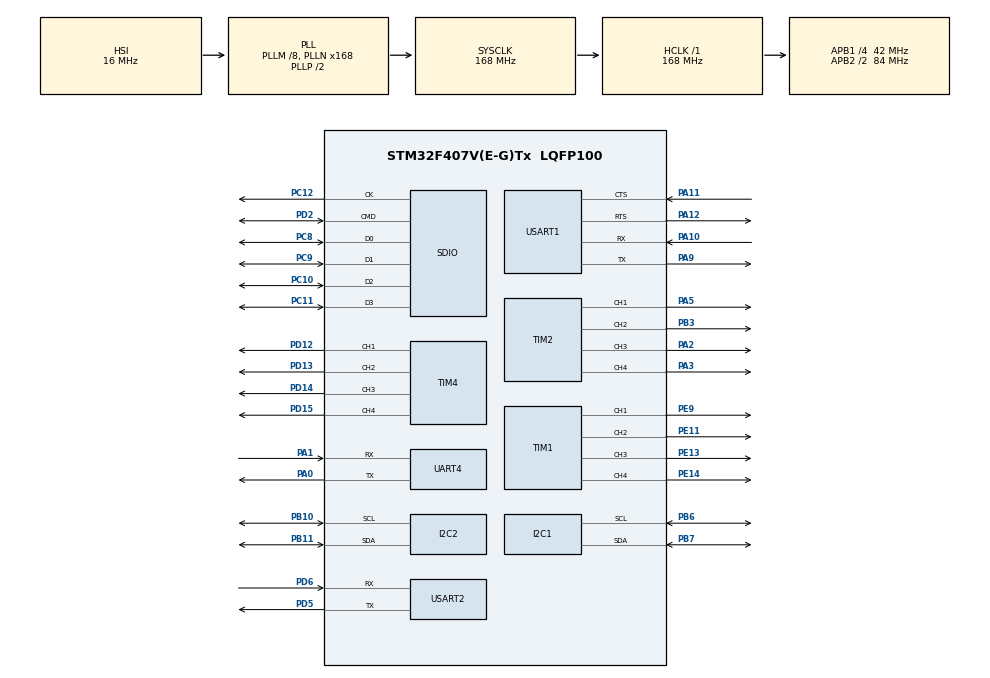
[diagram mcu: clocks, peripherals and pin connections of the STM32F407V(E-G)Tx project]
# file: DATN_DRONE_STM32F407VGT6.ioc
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FREERTOS.Tasks01=defaultTask,0,128,StartDefaultTask,Default,NULL,Dynamic,NULL,NULL
Mcu.Family=STM32F4
Mcu.Name=STM32F407V(E-G)Tx
Mcu.Package=LQFP100
NVIC.PriorityGroup=NVIC_PRIORITYGROUP_4
NVIC.TIM8_TRG_COM_TIM14_IRQn=true\:15\:0\:false\:false\:true\:false\:false\:true\:true
NVIC.TimeBase=TIM8_TRG_COM_TIM14_IRQn
NVIC.TimeBaseIP=TIM14
PA0-WKUP.Mode=Asynchronous
PA0-WKUP.Signal=UART4_TX
PA1.Mode=Asynchronous
PA1.Signal=UART4_RX
PA10.Mode=Asynchronous
PA10.Signal=USART1_RX
PA11.Mode=CTS_RTS
PA11.Signal=USART1_CTS
PA12.Mode=CTS_RTS
PA12.Signal=USART1_RTS
PA13.Mode=Serial_Wire
PA13.Signal=SYS_JTMS-SWDIO
PA14.Mode=Serial_Wire
PA14.Signal=SYS_JTCK-SWCLK
PA2.Signal=S_TIM2_CH3
PA3.Signal=S_TIM2_CH4
PA5.Signal=S_TIM2_CH1_ETR
PA9.Mode=Asynchronous
PA9.Signal=USART1_TX
PB10.Mode=I2C
PB10.Signal=I2C2_SCL
PB11.Mode=I2C
PB11.Signal=I2C2_SDA
PB3.Signal=S_TIM2_CH2
PB6.Mode=I2C
PB6.Signal=I2C1_SCL
PB7.Mode=I2C
PB7.Signal=I2C1_SDA
PC10.Mode=SD_4_bits_Wide_bus
PC10.Signal=SDIO_D2
PC11.Mode=SD_4_bits_Wide_bus
PC11.Signal=SDIO_D3
PC12.Mode=SD_4_bits_Wide_bus
PC12.Signal=SDIO_CK
PC8.Mode=SD_4_bits_Wide_bus
PC8.Signal=SDIO_D0
PC9.Mode=SD_4_bits_Wide_bus
PC9.Signal=SDIO_D1
PD12.Signal=S_TIM4_CH1
PD13.Signal=S_TIM4_CH2
PD14.Signal=S_TIM4_CH3
PD15.Signal=S_TIM4_CH4
PD2.Mode=SD_4_bits_Wide_bus
PD2.Signal=SDIO_CMD
PD5.Mode=Asynchronous
PD5.Signal=USART2_TX
PD6.Mode=Asynchronous
PD6.Signal=USART2_RX
PE11.Signal=S_TIM1_CH2
PE13.Signal=S_TIM1_CH3
PE14.Signal=S_TIM1_CH4
PE9.Signal=S_TIM1_CH1
PH0-OSC_IN.Mode=HSE-External-Oscillator
PH0-OSC_IN.Signal=RCC_OSC_IN
PH1-OSC_OUT.Mode=HSE-External-Oscillator
PH1-OSC_OUT.Signal=RCC_OSC_OUT
ProjectManager.HeapSize=0x200
ProjectManager.StackSize=0x400
ProjectManager.TargetToolchain=STM32CubeIDE
RCC.48MHZClocksFreq_Value=48000000
RCC.AHBFreq_Value=168000000
RCC.APB1CLKDivider=RCC_HCLK_DIV4
RCC.APB1Freq_Value=42000000
RCC.APB1TimFreq_Value=84000000
RCC.APB2CLKDivider=RCC_HCLK_DIV2
RCC.APB2Freq_Value=84000000
RCC.APB2TimFreq_Value=168000000
RCC.CortexFreq_Value=168000000
RCC.HCLKFreq_Value=168000000
RCC.HSE_VALUE=25000000
RCC.HSI_VALUE=16000000
RCC.LSE_VALUE=32768
RCC.PLLM=8
RCC.PLLN=168
RCC.PLLQ=7
RCC.SYSCLKFreq_VALUE=168000000
RCC.SYSCLKSource=RCC_SYSCLKSOURCE_PLLCLK
RCC.VCOOutputFreq_Value=336000000
SH.S_TIM1_CH1.0=TIM1_CH1,Output Compare1 CH1
SH.S_TIM1_CH2.0=TIM1_CH2,Output Compare2 CH2
SH.S_TIM1_CH3.0=TIM1_CH3,PWM Generation3 CH3
SH.S_TIM1_CH4.0=TIM1_CH4,PWM Generation4 CH4
SH.S_TIM2_CH1_ETR.0=TIM2_CH1,PWM Generation1 CH1
SH.S_TIM2_CH2.0=TIM2_CH2,PWM Generation2 CH2
SH.S_TIM2_CH3.0=TIM2_CH3,PWM Generation3 CH3
SH.S_TIM2_CH4.0=TIM2_CH4,PWM Generation4 CH4
SH.S_TIM4_CH1.0=TIM4_CH1,PWM Generation1 CH1
SH.S_TIM4_CH2.0=TIM4_CH2,PWM Generation2 CH2
SH.S_TIM4_CH3.0=TIM4_CH3,PWM Generation3 CH3
SH.S_TIM4_CH4.0=TIM4_CH4,PWM Generation4 CH4
TIM1.Channel-Output\ Compare1\ CH1=TIM_CHANNEL_1
TIM1.Channel-Output\ Compare2\ CH2=TIM_CHANNEL_2
TIM1.Channel-PWM\ Generation3\ CH3=TIM_CHANNEL_3
TIM1.Channel-PWM\ Generation4\ CH4=TIM_CHANNEL_4
TIM2.Channel-PWM\ Generation1\ CH1=TIM_CHANNEL_1
TIM2.Channel-PWM\ Generation2\ CH2=TIM_CHANNEL_2
TIM2.Channel-PWM\ Generation3\ CH3=TIM_CHANNEL_3
TIM2.Channel-PWM\ Generation4\ CH4=TIM_CHANNEL_4
TIM4.Channel-PWM\ Generation1\ CH1=TIM_CHANNEL_1
TIM4.Channel-PWM\ Generation2\ CH2=TIM_CHANNEL_2
TIM4.Channel-PWM\ Generation3\ CH3=TIM_CHANNEL_3
TIM4.Channel-PWM\ Generation4\ CH4=TIM_CHANNEL_4
UART4.VirtualMode=Asynchronous
USART1.VirtualMode=VM_ASYNC
USART2.VirtualMode=VM_ASYNC
VP_FREERTOS_VS_CMSIS_V1.Mode=CMSIS_V1
VP_SYS_VS_tim14.Mode=TIM14
VP_TIM1_VS_ClockSourceINT.Mode=Internal
VP_TIM2_VS_ClockSourceINT.Mode=Internal
VP_TIM4_VS_ClockSourceINT.Mode=Internal
board=custom

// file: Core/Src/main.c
/* USER CODE BEGIN Header */
/**
 ******************************************************************************
 * @file           : main.c
 * @brief          : Main program body
 ******************************************************************************
 * @attention
 *
 * Copyright (c) 2026 STMicroelectronics.
 * All rights reserved.
 *
 * This software is licensed under terms that can be found in the LICENSE file
 * in the root directory of this software component.
 * If no LICENSE file comes with this software, it is provided AS-IS.
 *
 ******************************************************************************
 */
/* USER CODE END Header */
#include "main.h"
#include "cmsis_os.h"
#include "i2c.h"
#include "sdio.h"
#include "tim.h"
#include "usart.h"
#include "gpio.h"

#include "app_main.h"

void SystemClock_Config(void);
void MX_FREERTOS_Init(void);

int main(void)
{

	/* MCU Configuration--------------------------------------------------------*/

	/* Reset of all peripherals, Initializes the Flash interface and the Systick. */
	HAL_Init();

	/* Configure the system clock */
	SystemClock_Config();

	/* Initialize all configured peripherals */
	MX_GPIO_Init();
	MX_I2C1_Init();
	MX_I2C2_Init();
	MX_SDIO_SD_Init();
	MX_TIM1_Init();
	MX_TIM2_Init();
	MX_TIM4_Init();
	MX_UART4_Init();
	MX_USART1_UART_Init();
	MX_USART2_UART_Init();
	/* USER CODE BEGIN 2 */
	if( createTasks() && initTasks())
	{
		// turn led
	}
	else
	{
		// khong cho chay chuong trinh
		while(1);
	}
	/* USER CODE END 2 */

	/* Call init function for freertos objects (in cmsis_os2.c) */
	MX_FREERTOS_Init();

	/* Start scheduler */
	//osKernelStart();
	vTaskStartScheduler();
	/* We should never get here as control is now taken by the scheduler */

	/* Infinite loop */
	while (1)
	{

	}
}

void SystemClock_Config(void)
{
	RCC_OscInitTypeDef RCC_OscInitStruct = {0};
	RCC_ClkInitTypeDef RCC_ClkInitStruct = {0};

	/** Configure the main internal regulator output voltage
	 */
	__HAL_RCC_PWR_CLK_ENABLE();
	__HAL_PWR_VOLTAGESCALING_CONFIG(PWR_REGULATOR_VOLTAGE_SCALE1);

	/** Initializes the RCC Oscillators according to the specified parameters
	 * in the RCC_OscInitTypeDef structure.
	 */
	RCC_OscInitStruct.OscillatorType = RCC_OSCILLATORTYPE_HSI;
	RCC_OscInitStruct.HSIState = RCC_HSI_ON;
	RCC_OscInitStruct.HSICalibrationValue = RCC_HSICALIBRATION_DEFAULT;
	RCC_OscInitStruct.PLL.PLLState = RCC_PLL_ON;
	RCC_OscInitStruct.PLL.PLLSource = RCC_PLLSOURCE_HSI;
	RCC_OscInitStruct.PLL.PLLM = 8;
	RCC_OscInitStruct.PLL.PLLN = 168;
	RCC_OscInitStruct.PLL.PLLP = RCC_PLLP_DIV2;
	RCC_OscInitStruct.PLL.PLLQ = 7;
	if (HAL_RCC_OscConfig(&RCC_OscInitStruct) != HAL_OK)
	{
		Error_Handler();
	}

	/** Initializes the CPU, AHB and APB buses clocks
	 */
	RCC_ClkInitStruct.ClockType = RCC_CLOCKTYPE_HCLK|RCC_CLOCKTYPE_SYSCLK
			|RCC_CLOCKTYPE_PCLK1|RCC_CLOCKTYPE_PCLK2;
	RCC_ClkInitStruct.SYSCLKSource = RCC_SYSCLKSOURCE_PLLCLK;
	RCC_ClkInitStruct.AHBCLKDivider = RCC_SYSCLK_DIV1;
	RCC_ClkInitStruct.APB1CLKDivider = RCC_HCLK_DIV4;
	RCC_ClkInitStruct.APB2CLKDivider = RCC_HCLK_DIV2;

	if (HAL_RCC_ClockConfig(&RCC_ClkInitStruct, FLASH_LATENCY_5) != HAL_OK)
	{
		Error_Handler();
	}
}

void HAL_TIM_PeriodElapsedCallback(TIM_HandleTypeDef *htim)
{
	if (htim->Instance == TIM14)
	{
		HAL_IncTick();
	}
}

void Error_Handler(void)
{
	__disable_irq();
	while (1)
	{
	}
}
